AUTOSAR XML (schema 00046)
package /ComponentTypes
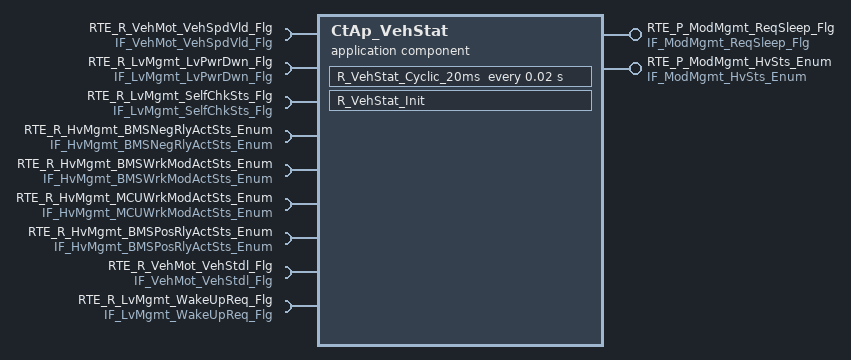
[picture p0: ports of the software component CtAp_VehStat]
  application sw component type CtAp_VehStat
    provide port RTE_P_ModMgmt_ReqSleep_Flg: nonqueued-sender-com-spec{data-element=tec_ModMgmt_ReqSleep_Flg, init-value=0}, provided-interface=IF_ModMgmt_ReqSleep_Flg
    provide port RTE_P_ModMgmt_HvSts_Enum: nonqueued-sender-com-spec{data-element=tec_ModMgmt_HvSts_Enum, init-value=0}, provided-interface=IF_ModMgmt_HvSts_Enum
    9 x require port:
      RTE_R_VehMot_VehSpdVld_Flg: nonqueued-receiver-com-spec{data-element=tec_VehMot_VehSpdVld_Flg, filter=data-filter-type=ALWAYS, init-value=0}, required-interface=IF_VehMot_VehSpdVld_Flg
      RTE_R_LvMgmt_LvPwrDwn_Flg: nonqueued-receiver-com-spec{data-element=tec_LvMgmt_LvPwrDwn_Flg, filter=data-filter-type=ALWAYS, init-value=0}, required-interface=IF_LvMgmt_LvPwrDwn_Flg
      RTE_R_LvMgmt_SelfChkSts_Flg: nonqueued-receiver-com-spec{data-element=tec_LvMgmt_SelfChkSts_Flg, filter=data-filter-type=ALWAYS, init-value=0}, required-interface=IF_LvMgmt_SelfChkSts_Flg
      RTE_R_HvMgmt_BMSNegRlyActSts_Enum: nonqueued-receiver-com-spec{data-element=tec_HvMgmt_BMSNegRlyActSts_Enum, filter=data-filter-type=ALWAYS, init-value=0}, required-interface=IF_HvMgmt_BMSNegRlyActSts_Enum
      RTE_R_HvMgmt_BMSWrkModActSts_Enum: nonqueued-receiver-com-spec{data-element=tec_HvMgmt_BMSWrkModActSts_Enum, filter=data-filter-type=ALWAYS, init-value=0}, required-interface=IF_HvMgmt_BMSWrkModActSts_Enum
      RTE_R_HvMgmt_MCUWrkModActSts_Enum: nonqueued-receiver-com-spec{data-element=tec_HvMgmt_MCUWrkModActSts_Enum, filter=data-filter-type=ALWAYS, init-value=0}, required-interface=IF_HvMgmt_MCUWrkModActSts_Enum
      RTE_R_HvMgmt_BMSPosRlyActSts_Enum: nonqueued-receiver-com-spec{data-element=tec_HvMgmt_BMSPosRlyActSts_Enum, filter=data-filter-type=ALWAYS, init-value=0}, required-interface=IF_HvMgmt_BMSPosRlyActSts_Enum
      RTE_R_VehMot_VehStdl_Flg: nonqueued-receiver-com-spec{data-element=tec_VehMot_VehStdl_Flg, filter=data-filter-type=ALWAYS, init-value=0}, required-interface=IF_VehMot_VehStdl_Flg
      RTE_R_LvMgmt_WakeUpReq_Flg: nonqueued-receiver-com-spec{data-element=tec_LvMgmt_WakeUpReq_Flg, filter=data-filter-type=ALWAYS, init-value=0}, required-interface=IF_LvMgmt_WakeUpReq_Flg
    behavior CtAp_VehStat_InternalBehavior
      timing event TMT_R_VehStat_Cyclic_20ms: start-on-event=R_VehStat_Cyclic_20ms, period=0.02
      init event CtAp_VehStat_InitEvent: start-on-event=R_VehStat_Init
      runnable R_VehStat_Cyclic_20ms
        data-receive-point-by-arguments:
          9 x access:
            REC_RTE_R_HvMgmt_BMSNegRlyActSts_Enum_tec_HvMgmt_BMSNegRlyActSts_Enum: accessed-variable=RTE_R_HvMgmt_BMSNegRlyActSts_Enum.tec_HvMgmt_BMSNegRlyActSts_Enum
            REC_RTE_R_HvMgmt_BMSPosRlyActSts_Enum_tec_HvMgmt_BMSPosRlyActSts_Enum: accessed-variable=RTE_R_HvMgmt_BMSPosRlyActSts_Enum.tec_HvMgmt_BMSPosRlyActSts_Enum
            REC_RTE_R_HvMgmt_BMSWrkModActSts_Enum_tec_HvMgmt_BMSWrkModActSts_Enum: accessed-variable=RTE_R_HvMgmt_BMSWrkModActSts_Enum.tec_HvMgmt_BMSWrkModActSts_Enum
            REC_RTE_R_HvMgmt_MCUWrkModActSts_Enum_tec_HvMgmt_MCUWrkModActSts_Enum: accessed-variable=RTE_R_HvMgmt_MCUWrkModActSts_Enum.tec_HvMgmt_MCUWrkModActSts_Enum
            REC_RTE_R_LvMgmt_LvPwrDwn_Flg_tec_LvMgmt_LvPwrDwn_Flg: accessed-variable=RTE_R_LvMgmt_LvPwrDwn_Flg.tec_LvMgmt_LvPwrDwn_Flg
            REC_RTE_R_LvMgmt_SelfChkSts_Flg_tec_LvMgmt_SelfChkSts_Flg: accessed-variable=RTE_R_LvMgmt_SelfChkSts_Flg.tec_LvMgmt_SelfChkSts_Flg
            REC_RTE_R_VehMot_VehSpdVld_Flg_tec_VehMot_VehSpdVld_Flg: accessed-variable=RTE_R_VehMot_VehSpdVld_Flg.tec_VehMot_VehSpdVld_Flg
            REC_RTE_R_VehMot_VehStdl_Flg_tec_VehMot_VehStdl_Flg: accessed-variable=RTE_R_VehMot_VehStdl_Flg.tec_VehMot_VehStdl_Flg
            REC_RTE_R_LvMgmt_WakeUpReq_Flg_tec_LvMgmt_WakeUpReq_Flg: accessed-variable=RTE_R_LvMgmt_WakeUpReq_Flg.tec_LvMgmt_WakeUpReq_Flg
        data-send-points:
          access SEND_RTE_P_ModMgmt_HvSts_Enum_tec_ModMgmt_HvSts_Enum: accessed-variable=RTE_P_ModMgmt_HvSts_Enum.tec_ModMgmt_HvSts_Enum
          access SEND_RTE_P_ModMgmt_ReqSleep_Flg_tec_ModMgmt_ReqSleep_Flg: accessed-variable=RTE_P_ModMgmt_ReqSleep_Flg.tec_ModMgmt_ReqSleep_Flg
      runnable R_VehStat_Init
  swc implementation CtAp_VehStat_Implementation: behavior=CtAp_VehStat_InternalBehavior
